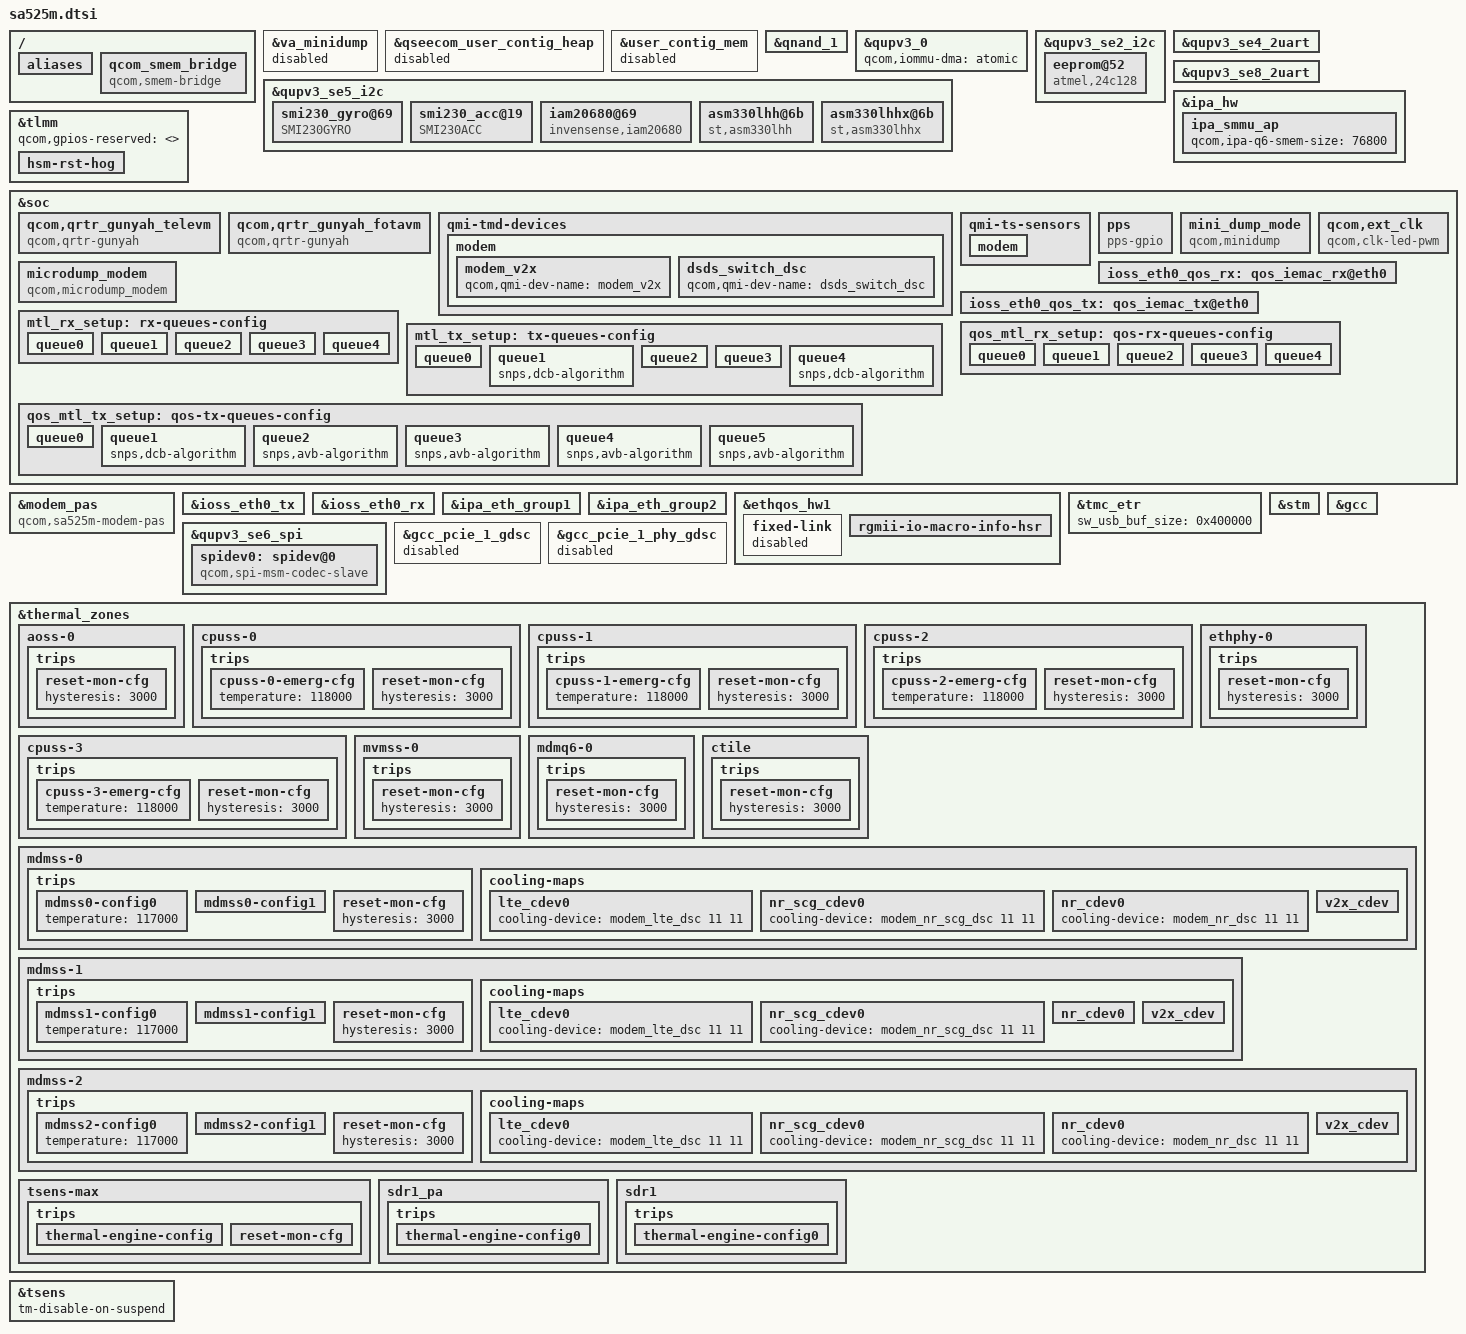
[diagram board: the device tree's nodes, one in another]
// SPDX-License-Identifier: BSD-3-Clause
/*
 * Copyright (c) Qualcomm Technologies, Inc. and/or its subsidiaries.
 */

#include "sdxpinn.dtsi"
#include "sa525m-pmic-overlay.dtsi"
#include "sa525m-mhi.dtsi"

/ {
	aliases {
		spi6 = &qupv3_se6_spi;
		hsuart1 = &qupv3_se4_2uart;
		hsuart2 = &qupv3_se8_2uart;
	};

    qcom_smem_bridge {
        compatible = "qcom,smem-bridge";
        qcom,smem-item = <627>;
        qcom,smem-offset = <0>;
	};
};

&va_minidump {
	/delete-property/ memory-region;

	status = "disabled";
};

/delete-node/ &va_md_mem;

&qseecom_user_contig_heap {
	status = "disabled";
};

&user_contig_mem {
	status = "disabled";
};

&qnand_1 {
	status = "ok";
	nvmem-cells = <&boot_config>;
	nvmem-cell-names = "boot_conf";

	/* Storage boot device fuse is present in QFPROM_RAW_OEM_CONFIG_ROW0_LSB
	 * this fuse is blown by bootloader and populated in boot_config
	 * register[1:4] FAST_BOOT bits.
	 *
	 * FAST_BOOT bits might vary from target to target. It could be [1:3] or [1:4] or [1:5].
	 * So, mention the number of FAST_BOOT bits used for this target.
	 */
	qcom,boot_dev_bits = <0x4>;

	/* Boot device detection value (FAST_BOOT bits) for NAND/eMMC,
	 * which might varies from target to target.
	 */
	qcom,nand_boot = <0x0 0x4 0x5>;
};

&qupv3_0 {
	qcom,iommu-dma = "atomic";
};

&qupv3_se5_i2c {
	status = "okay";
	smi230_gyro@69 {
		compatible = "SMI230GYRO";
		reg = <0x69>;
		pinctrl-names = "default";
		pinctrl-0 = <&sensor_int1_default>;
		interrupt-parent = <&tlmm>;
		interrupts = <109 IRQ_TYPE_EDGE_RISING>;
		gpio_irq = <&tlmm 109 IRQ_TYPE_EDGE_RISING>;
	};

	smi230_acc@19 {
		compatible = "SMI230ACC";
		reg = <0x19>;
		pinctrl-names = "default";
		pinctrl-0 = <&sensor_int2_default>;
		interrupt-parent = <&tlmm>;
		interrupts = <108 IRQ_TYPE_EDGE_RISING>;
		gpio_irq = <&tlmm 108 IRQ_TYPE_EDGE_RISING>;
	};

	iam20680@69 {
		compatible = "invensense,iam20680";
		reg = <0x69>;
		pinctrl-names = "default";
		pinctrl-0 = <&sensor_int1_default>;
		interrupt-parent = <&tlmm>;
		interrupts = <108 IRQ_TYPE_EDGE_RISING>;
		axis_map_x = <1>;
		axis_map_y = <0>;
		axis_map_z = <2>;
		negate_x = <1>;
		negate_y = <0>;
		negate_z = <0>;
		inven,secondary_type = "none";
		inven,aux_type = "none";
		inven,read_only_slave_type = "none";
	};

	asm330lhh@6b {
		compatible = "st,asm330lhh";
		reg = <0x6b>;
		pinctrl-names = "default";
		pinctrl-0 = <&sensor_int1_default>,<&sensor_int2_default>;
		interrupt-parent = <&tlmm>;
		interrupts = <109 IRQ_TYPE_EDGE_RISING>;
		st,drdy-int-pin= <2>;
		qcom,regulator_check = <0>;
		qcom,asm330_hrtimer;
	};

	asm330lhhx@6b {
		compatible = "st,asm330lhhx";
		reg = <0x6b>;
		pinctrl-names = "default";
		pinctrl-0 = <&sensor_int1_default>,<&sensor_int2_default>;
		interrupt-parent = <&tlmm>;
		interrupts = <109 IRQ_TYPE_EDGE_RISING>;
		st,int-pin= <2>;
		qcom,regulator_check = <0>;
		qcom,asm330_hrtimer;
	};
};

&qupv3_se2_i2c {
	status = "ok" ;
	eeprom@52 {
		compatible = "atmel,24c128";
		reg = <0x52>;
		pagesize = <32>;
	};
};

&qupv3_se4_2uart {
	status = "ok";
};

&qupv3_se8_2uart {
	status = "ok";
};


&ipa_hw {
	qcom,ipa-config-is-auto;
	qcom,ipa-wdi2_over_gsi;
	qcom,msm-bus,name = "ipa";
	pas-ids = <0xf>;
	firmware-names = "ipa_fws";
	memory-regions = <&ipa_fw_mem>;
	/delete-property/ qcom,use-xbl-boot;
	/delete-property/ qcom,lan-coal-enable;
	ipa_smmu_ap: ipa_smmu_ap {
		qcom,ipa-q6-smem-size = <76800>;
	};
};

&tlmm {
	qcom,gpios-reserved = <>;
};

&soc {
	qcom,qrtr_gunyah_televm {
		compatible = "qcom,qrtr-gunyah";
		qcom,master;
		qcom,net-id = <8>;
		gunyah-label = <3>;
		peer-name = <5>;
	};

	qcom,qrtr_gunyah_fotavm {
		compatible = "qcom,qrtr-gunyah";
		qcom,master;
		qcom,net-id = <10>;
		gunyah-label = <9>;
		peer-name = <6>;
	};

	qmi-tmd-devices {
		modem {
			modem_v2x: modem_v2x {
				qcom,qmi-dev-name = "modem_v2x";
				#cooling-cells = <2>;
			};

			dsds_switch_dsc: dsds_switch_dsc {
				qcom,qmi-dev-name = "dsds_switch_dsc";
				#cooling-cells = <2>;
			};
		};
	};

	qmi-ts-sensors {
		modem {
			qcom,qmi-sensor-names = "sdr0",
						"sdr1",
						"sdr0_pa",
						"sdr1_pa",
						"mmw0",
						"mmw1",
						"mmw2",
						"mmw3",
						"mmw_ific0",
						"epm0",
						"epm1",
						"epm2",
						"epm3",
						"epm4",
						"epm5",
						"epm6",
						"epm7";
		};
	};

	pps {
		compatible = "pps-gpio";
		pinctrl-names = "default";
		pinctrl-0 = <&pinctrl_pps>;
		gpios = <&tlmm 104 GPIO_ACTIVE_HIGH>;
		interrupt-parent = <&tlmm>;
		interrupts = <104 IRQ_TYPE_EDGE_RISING>;
		status = "okay";
	};

	mini_dump_mode {
		compatible = "qcom,minidump";
		status = "ok";
	};

	microdump_modem {
		compatible = "qcom,microdump_modem";
	};

	qcom,ext_clk {
		compatible = "qcom,clk-led-pwm";
		clocks = <&gcc GCC_TLMM_125_CLK>,
			<&rpmhcc RPMH_RF_CLK5>;
		clock-names = "core",
			"rf_clk5";
		assigned-clocks = <&gcc GCC_TLMM_125_CLK>;
		assigned-clock-rates = <125000000>;
		qcom,max_duty = <50>;
		pinctrl-names = "active", "sleep";
		pinctrl-0 = <&qcom_125_clk_active>;
		pinctrl-1 = <&qcom_125_clk_sleep>;
		status = "ok";
	};

	ioss_eth0_qos_rx: qos_iemac_rx@eth0 {
		qcom,dir-rx;
		qcom,rx-filter-be;

		qcom,ring-size = <512>;
		qcom,buff-size = <2048>;

		qcom,mod-count-min = <32>;
		qcom,mod-count-max = <32>;
		qcom,mod-usecs-min = <30>;
		qcom,mod-usecs-max = <60>;
	};

	ioss_eth0_qos_tx: qos_iemac_tx@eth0 {
		qcom,dir-tx;
		qcom,ring-size = <512>;
		qcom,buff-size = <2048>;

		qcom,mod-count-min = <32>;
		qcom,mod-count-max = <32>;
		qcom,mod-usecs-min = <30>;
		qcom,mod-usecs-max = <60>;
	};

	mtl_rx_setup: rx-queues-config {
		snps,rx-queues-to-use = <5>;
		snps,rx-sched-sp;

		queue0 {
			snps,dcb-algorithm;
			snps,route-up;
			snps,threshold_byte = <64>;
			qcom,ipa_offload;
			snps,fifo_depth = <8192>;
			snps,map-to-dma-channel = <0x1>;
		};

		queue1 {
			snps,dcb-algorithm;
			snps,fifo_depth = <2048>;
			snps,map-to-dma-channel = <0x1>;
			snps,route-ptp;
			snps,route-multi-broad;
		};

		queue2 {
			snps,avb-algorithm;
			snps,fifo_depth = <2048>;
			snps,map-to-dma-channel = <0x2>;
			snps,route-avcp;
		};

		queue3 {
			snps,avb-algorithm;
			snps,fifo_depth = <4096>;
			snps,map-to-dma-channel = <0x3>;
			snps,priority = <0xC>;
		};

		queue4 {
			snps,dcb-algorithm;
			snps,fifo_depth = <4096>;
			snps,map-to-dma-channel = <0x4>;
		};
	};

	mtl_tx_setup: tx-queues-config {
		snps,tx-queues-to-use = <5>;
		snps,tx-sched-sp;

		queue0 {
			snps,dcb-algorithm;
			qcom,ipa_offload;
		};

		queue1 {
			snps,dcb-algorithm;
		};

		queue2 {
			snps,avb-algorithm;
			snps,send_slope = <0x1000>;
			snps,idle_slope = <0x1000>;
			snps,high_credit = <0x3E800>;
			snps,low_credit = <0xFFC18000>;
		};

		queue3 {
			snps,avb-algorithm;
			snps,send_slope = <0x1000>;
			snps,idle_slope = <0x1000>;
			snps,high_credit = <0x3E800>;
			snps,low_credit = <0xFFC18000>;
		};

		queue4 {
			snps,dcb-algorithm;
		};
	};

	qos_mtl_rx_setup: qos-rx-queues-config {
		qcom,config-name = "qos";
		snps,rx-queues-to-use = <5>;
		snps,rx-sched-sp;

		queue0 {
			snps,dcb-algorithm;
			snps,route-up;
			snps,threshold_byte = <64>;
			qcom,ipa_offload;
			snps,fifo_depth = <8192>;
			snps,map-to-dma-channel = <0x1>;
		};

		queue1 {
			snps,dcb-algorithm;
			snps,map-to-dma-channel = <0x1>;
			snps,fifo_depth = <3072>;
		};

		queue2 {
			snps,dcb-algorithm;
			snps,route-ptp;
			snps,fifo_depth = <3072>;
		};

		queue3 {
			snps,dcb-algorithm;
			snps,fifo_depth = <3072>;
		};

		queue4 {
			snps,dcb-algorithm;
			snps,fifo_depth = <3072>;
		};
	};

	qos_mtl_tx_setup: qos-tx-queues-config {
		qcom,config-name = "qos";
		snps,tx-queues-to-use = <6>;
		snps,tx-sched-sp;

		queue0 {
			snps,dcb-algorithm;
			qcom,ipa_offload;
		};

		queue1 {
			snps,dcb-algorithm;
		};

		queue2 {
			snps,avb-algorithm;
		};

		queue3 {
			snps,avb-algorithm;
		};

		queue4 {
			snps,avb-algorithm;
		};

		queue5 {
			snps,avb-algorithm;
		};
	};
};

&modem_pas  {
	compatible = "qcom,sa525m-modem-pas";
};

&ioss_eth0_tx {
	qcom,dir-tx;

	qcom,ring-size = <1023>;
	qcom,buff-size = <2048>;

	qcom,mod-count-min = <16>;
	qcom,mod-count-max = <16>;
	qcom,mod-usecs-min = <30>;
	qcom,mod-usecs-max = <60>;
};

&ioss_eth0_rx {
	qcom,dir-rx;
	qcom,rx-filter-be;

	qcom,ring-size = <1023>;
	qcom,buff-size = <2048>;

	qcom,mod-count-min = <16>;
	qcom,mod-count-max = <16>;
	qcom,mod-usecs-min = <30>;
	qcom,mod-usecs-max = <60>;
};

&ipa_eth_group1 {
	qcom,iommu-dma-addr-pool = <0x80000000 0x07E00000>;
	qcom,iommu-dma = "atomic";
};

&ipa_eth_group2 {
	qcom,iommu-dma-addr-pool = <0x87f10000 0x07f00000>;
	qcom,iommu-dma = "atomic";
};

&ethqos_hw1 {
		clocks =<&gcc GCC_EEE_EMAC0_CLK>,
			<&gcc GCC_EMAC0_AXI_CLK>,
			<&gcc GCC_EMAC0_CC_SGMIIPHY_RX_CLK>,
			<&gcc GCC_EMAC0_CC_SGMIIPHY_TX_CLK>,
			<&gcc GCC_EMAC0_PHY_AUX_CLK>,
			<&gcc GCC_EMAC0_PTP_CLK>,
			<&gcc GCC_EMAC0_RGMII_CLK>,
			<&gcc GCC_EMAC0_RPCS_RX_CLK>,
			<&gcc GCC_EMAC0_RPCS_TX_CLK>,
			<&gcc GCC_EMAC0_SLV_AHB_CLK>,
			<&gcc GCC_EMAC0_XGXS_RX_CLK>,
			<&gcc GCC_EMAC0_XGXS_TX_CLK>,
			<&gcc GCC_EMAC0_CC_SGMIIPHY_RX_CLK_SRC>,
			<&gcc GCC_EMAC0_CC_SGMIIPHY_TX_CLK_SRC>,
			<&gcc GCC_EMAC0_SGMIIPHY_MAC_RCLK_SRC>,
			<&gcc GCC_EMAC0_SGMIIPHY_MAC_TCLK_SRC>,
			<&emac0_sgmiiphy_rclk>,
			<&emac0_sgmiiphy_tclk>,
			<&emac0_sgmiiphy_mac_rclk>,
			<&emac0_sgmiiphy_mac_tclk>,
			<&gcc GCC_EMAC_0_CLKREF_EN>;
		clock-names = "eee", "stmmaceth", "sgmii_rx",
		"sgmii_tx", "phyaux","ptp_ref", "rgmii",
		"pcs_rx", "pcs_tx", "pclk", "xgxs_rx",
		"xgxs_tx", "sgmii_rclk_src", "sgmii_tclk_src",
		"sgmii_mac_rclk_src", "sgmii_mac_tclk_src", "sgmii_rclk",
		"sgmii_tclk", "sgmii_mac_rclk", "sgmii_mac_tclk","sgmi_ref";

		qcom,ioss_qos_channels =
			<&ioss_eth0_qos_rx>,
			<&ioss_eth0_qos_tx>;

		snps,ptp-ref-clk-rate = <125000000>;
		snps,ptp-req-clk-rate = <57600000>;
		avb-vlan-id = <2>;
		snps,mtl-rx-config = <&mtl_rx_setup &qos_mtl_rx_setup>;
		snps,mtl-tx-config = <&mtl_tx_setup &qos_mtl_tx_setup>;
		cv2x-queue = <4>;
		mac-efuse-addr = <0x221C8318>;

		phy-mode = "sgmii";
		mac-mode = "sgmii";
		snps,phy-addr = <0>;
		managed = "auto";
		mac-address = [00 55 7B B5 7D f7];
		enable-pfc;

		qcom,ioss_auto_resume_disabled;
		qcom,flow-ctrl-disabled;
		emac-phy-off-suspend = <4>;
		c37-autoneg-en;

		tx-fifo-depth = <49152>;
		rx-fifo-depth = <20480>;

		resets = <&gcc GCC_EMAC0_RGMII_CLK_ARES>;
		reset-names = "emac0_rgmii_clk_ares";

		fixed-link {
			status = "disabled";
			speed = <2500>;
			full-duplex;
		};

		rgmii-io-macro-info-hsr {
			rgmii-io-macro-config = <0x40c04c03>;
			rgmii-io-macro-config2 = <0x2200a0>;
			sdcc-hc-reg-dll-config = <0xd642c>;
			sdcc-hc-reg-ddr-config = <0x80040868>;
			sdcc-hc-reg-dll-config2 = <0xa001>;
			sdcc-usr-ctl = <0x90106c0>;
			sdcc-test-ctl = <0x01400000>;
		};
};

&tmc_etr {
	sw_usb_buf_size = <0x400000>;
};

&tlmm {
	hsm-rst-hog {
		gpio-hog;
		gpios = <102 0>;
		output-high;
	};
};

&qupv3_se6_spi {
	status = "okay";
	spidev0: spidev@0 {
		compatible = "qcom,spi-msm-codec-slave";
		reg =<0>;
		spi-max-frequency = <50000000>;
	};
};

&stm {
	status = "okay";
};

&gcc {
	protected-clocks = <GCC_PCIE_1_AUX_CLK>, <GCC_PCIE_1_AUX_PHY_CLK_SRC>,
		<GCC_PCIE_1_CFG_AHB_CLK>, <GCC_PCIE_1_CLKREF_EN>,
		<GCC_PCIE_1_MSTR_AXI_CLK>, <GCC_PCIE_1_PHY_RCHNG_CLK>,
		<GCC_PCIE_1_PHY_RCHNG_CLK_SRC>, <GCC_PCIE_1_PIPE_CLK>,
		<GCC_PCIE_1_PIPE_CLK_SRC>, <GCC_PCIE_1_PIPE_DIV2_CLK>,
		<GCC_PCIE_1_PIPE_DIV2_CLK_SRC>, <GCC_PCIE_1_SLV_AXI_CLK>,
		<GCC_PCIE_1_SLV_Q2A_AXI_CLK>;
};

&gcc_pcie_1_gdsc {
	status = "disabled";
};

&gcc_pcie_1_phy_gdsc {
	status = "disabled";
};

&thermal_zones {
	aoss-0 {
		trips {
			reset-mon-cfg {
				hysteresis = <3000>;
			};
		};
	};

	cpuss-0 {
		trips {
			cpuss-0-emerg-cfg {
				temperature = <118000>;
			};

			reset-mon-cfg {
				hysteresis = <3000>;
			};
		};
	};

	cpuss-1 {
		trips {
			cpuss-1-emerg-cfg {
				temperature = <118000>;
			};

			reset-mon-cfg {
				hysteresis = <3000>;
			};
		};
	};

	cpuss-2 {
		trips {
			cpuss-2-emerg-cfg {
				temperature = <118000>;
			};

			reset-mon-cfg {
				hysteresis = <3000>;
			};
		};
	};

	cpuss-3 {
		trips {
			cpuss-3-emerg-cfg {
				temperature = <118000>;
			};

			reset-mon-cfg {
				hysteresis = <3000>;
			};
		};
	};

	ethphy-0 {
		trips {
			reset-mon-cfg {
				hysteresis = <3000>;
			};
		};
	};

	mvmss-0 {
		trips {
			reset-mon-cfg {
				hysteresis = <3000>;
			};
		};
	};

	mdmq6-0 {
		trips {
			reset-mon-cfg {
				hysteresis = <3000>;
			};
		};
	};

	ctile {
		trips {
			reset-mon-cfg {
				hysteresis = <3000>;
			};
		};
	};

	mdmss-0 {
		trips {
			mdmss0-config0 {
				temperature = <117000>;
			};

			mdmss0-config1 {
				temperature = <120000>;
				hysteresis = <2000>;
			};

			reset-mon-cfg {
				hysteresis = <3000>;
			};
		};

		cooling-maps {
			lte_cdev0 {
				cooling-device = <&modem_lte_dsc 11 11>;
			};

			nr_scg_cdev0 {
				cooling-device = <&modem_nr_scg_dsc 11 11>;
			};

			nr_cdev0 {
				cooling-device = <&modem_nr_dsc 11 11>;
			};

			v2x_cdev {
				trip = <&mdmss0_config1>;
				cooling-device = <&modem_v2x 3 3>;
			};
		};
	};

	mdmss-1 {
		trips {
			mdmss1-config0 {
				temperature = <117000>;
			};

			mdmss1-config1 {
				temperature = <120000>;
				hysteresis = <2000>;
			};

			reset-mon-cfg {
				hysteresis = <3000>;
			};
		};

		cooling-maps {
			lte_cdev0 {
				cooling-device = <&modem_lte_dsc 11 11>;
			};

			nr_scg_cdev0 {
				cooling-device = <&modem_nr_scg_dsc 11 11>;
			};

			nr_cdev0 {
				trip = <&mdmss1_config0>;
				cooling-device = <&modem_nr_dsc 11 11>;
			};

			v2x_cdev {
				trip = <&mdmss1_config1>;
				cooling-device = <&modem_v2x 3 3>;
			};
		};
	};

	mdmss-2 {
		trips {
			mdmss2-config0 {
				temperature = <117000>;
			};

			mdmss2-config1 {
				temperature = <120000>;
				hysteresis = <2000>;
			};

			reset-mon-cfg {
				hysteresis = <3000>;
			};
		};

		cooling-maps {
			lte_cdev0 {
				cooling-device = <&modem_lte_dsc 11 11>;
			};

			nr_scg_cdev0 {
				cooling-device = <&modem_nr_scg_dsc 11 11>;
			};

			nr_cdev0 {
				cooling-device = <&modem_nr_dsc 11 11>;
			};

			v2x_cdev {
				trip = <&mdmss2_config1>;
				cooling-device = <&modem_v2x 3 3>;
			};
		};
	};

	tsens-max {
		polling-delay-passive = <0>;
		polling-delay = <0>;
		thermal-sensors = <&tsens 129>;

		trips {
			thermal-engine-config {
				temperature = <135000>;
				hysteresis = <1000>;
				type = "passive";
			};

			reset-mon-cfg {
				temperature = <125000>;
				hysteresis = <5000>;
				type = "passive";
			};
		};
	};

	sdr1_pa {
		polling-delay-passive = <0>;
		polling-delay = <0>;
		thermal-sensors = <&qmi_sensor
				(QMI_MODEM_INST_ID+QMI_SDR1_PA)>;
		trips {
			thermal-engine-config0 {
				temperature = <125000>;
				hysteresis = <1000>;
				type = "passive";
			};
		};
	};

	sdr1 {
		polling-delay-passive = <0>;
		polling-delay = <0>;
		thermal-sensors = <&qmi_sensor
				(QMI_MODEM_INST_ID+QMI_SDR1)>;
		trips {
			thermal-engine-config0 {
				temperature = <125000>;
				hysteresis = <1000>;
				type = "passive";
			};
		};
	};
};

&tsens {
	tm-disable-on-suspend;
};
